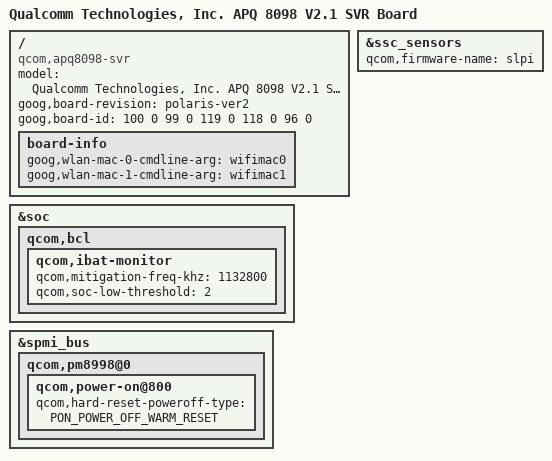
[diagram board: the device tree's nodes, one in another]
/* Copyright (c) 2016, The Linux Foundation. All rights reserved.
 *
 * This program is free software; you can redistribute it and/or modify
 * it under the terms of the GNU General Public License version 2 and
 * only version 2 as published by the Free Software Foundation.
 *
 * This program is distributed in the hope that it will be useful,
 * but WITHOUT ANY WARRANTY; without even the implied warranty of
 * MERCHANTABILITY or FITNESS FOR A PARTICULAR PURPOSE.  See the
 * GNU General Public License for more details.
 */


/dts-v1/;

#include "apq8098-v2.1.dtsi"
#include "msm8998-svr21.dtsi"

/ {
	model = "Qualcomm Technologies, Inc. APQ 8098 V2.1 SVR Board";
	compatible = "qcom,apq8098-svr", "qcom,apq8098", "qcom,svr";
        goog,board-revision = "polaris-ver2";
	/* Board-Id GPIOs: 0: 100, 1: 99, 2: 119, 3: 118, and 4: 96. */
	goog,board-id = <100 0 99 0 119 0 118 0 96 0>;

	board-info {
		goog,wlan-mac-0-cmdline-arg = "wifimac0";
		goog,wlan-mac-1-cmdline-arg = "wifimac1";
	};
};

&ssc_sensors {
   /* SLPI firmware files are spli.* */
   qcom,firmware-name = "slpi";
};

&soc {
  qcom,bcl {
    /delete-property/ qcom,bcl-hotplug-list;
    /delete-property/ qcom,bcl-soc-hotplug-list;
    qcom,ibat-monitor {
      qcom,mitigation-freq-khz = <1132800>;
      qcom,soc-low-threshold = <2>;

    };
  };
};

&spmi_bus {
	qcom,pm8998@0 {
		qcom,power-on@800 {
			qcom,hard-reset-poweroff-type = <PON_POWER_OFF_WARM_RESET>;
		};
	};
};

